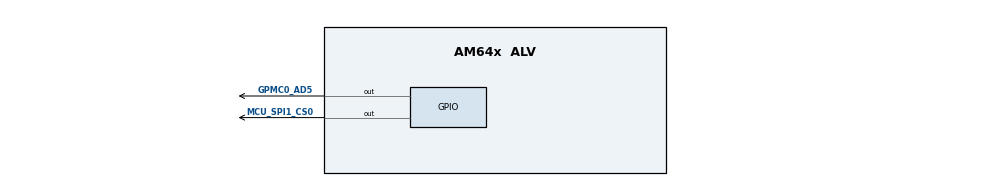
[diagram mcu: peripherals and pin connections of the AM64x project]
/**
 * @cliArgs --device "AM64x" --package "ALV" --part "Default" --context "r5fss0-0" --product "INDUSTRIAL_COMMUNICATIONS_SDK@09.01.00"
 * @versions {"tool":"1.19.0+3426"}
 */

/**
 * Import the modules used in this configuration.
 */
const eeprom     = scripting.addModule("/board/eeprom/eeprom", {}, false);
const eeprom1    = eeprom.addInstance();
const led        = scripting.addModule("/board/led/led", {}, false);
const led1       = led.addInstance();
const led2       = led.addInstance();
const led3       = led.addInstance();
const gpio       = scripting.addModule("/drivers/gpio/gpio", {}, false);
const gpio1      = gpio.addInstance();
const gpio2      = gpio.addInstance();
const gpio3      = gpio.addInstance();
const i2c        = scripting.addModule("/drivers/i2c/i2c", {}, false);
const i2c1       = i2c.addInstance();
const i2c2       = i2c.addInstance();
const ipc        = scripting.addModule("/drivers/ipc/ipc");
const pruicss    = scripting.addModule("/drivers/pruicss/pruicss", {}, false);
const pruicss1   = pruicss.addInstance();
const udma       = scripting.addModule("/drivers/udma/udma", {}, false);
const udma1      = udma.addInstance();
const profinet   = scripting.addModule("/industrial_comms/profinet/profinet", {}, false);
const profinet1  = profinet.addInstance();
const debug_log  = scripting.addModule("/kernel/dpl/debug_log");
const mpu_armv7  = scripting.addModule("/kernel/dpl/mpu_armv7", {}, false);
const mpu_armv71 = mpu_armv7.addInstance();
const mpu_armv72 = mpu_armv7.addInstance();
const mpu_armv73 = mpu_armv7.addInstance();
const mpu_armv74 = mpu_armv7.addInstance();
const mpu_armv75 = mpu_armv7.addInstance();
const mpu_armv76 = mpu_armv7.addInstance();
const mpu_armv77 = mpu_armv7.addInstance();
const mpu_armv78 = mpu_armv7.addInstance();
const mpu_armv79 = mpu_armv7.addInstance();

/**
 * Write custom configuration values to the imported modules.
 */
eeprom1.$name = "CONFIG_EEPROM0";

led1.$name = "CONFIG_LED0";

led2.$name = "CONFIG_LED1";

led3.$name = "CONFIG_LED2";
led3.name  = "TPIC2810";

gpio1.pinDir                   = "OUTPUT";
gpio1.useMcuDomainPeripherals  = true;
gpio1.$name                    = "CONFIG_GPIO2";
gpio1.MCU_GPIO.$assign         = "MCU_GPIO0";
gpio1.MCU_GPIO.gpioPin.$assign = "MCU_SPI1_CS0";

gpio2.pinDir               = "OUTPUT";
gpio2.$name                = "CONFIG_GPIO0";
led1.peripheralDriver      = gpio2;
gpio2.GPIO.$assign         = "GPIO0";
gpio2.GPIO.gpioPin.$assign = "GPMC0_AD5";

gpio3.$name           = "CONFIG_GPIO1";
led2.peripheralDriver = gpio3;
gpio3.GPIO.$assign    = "GPIO1";

i2c1.$name               = "CONFIG_I2C0";
eeprom1.peripheralDriver = i2c1;
led3.peripheralDriver    = i2c1;
i2c1.I2C.$assign         = "I2C0";
i2c1.I2C.SCL.$assign     = "I2C0_SCL";
i2c1.I2C.SDA.$assign     = "I2C0_SDA";

i2c2.$name           = "CONFIG_I2C1";
i2c2.I2C.$assign     = "I2C1";
i2c2.I2C.SCL.$assign = "I2C1_SCL";
i2c2.I2C.SDA.$assign = "I2C1_SDA";

ipc.r5fss1_0 = "NONE";
ipc.r5fss1_1 = "NONE";
ipc.m4fss0_0 = "NONE";

udma1.$name    = "CONFIG_UDMA_PKTDMA0";
udma1.instance = "PKTDMA_0";

profinet1.$name                         = "CONFIG_PROFINET0";
profinet1.icss_emac[0].$name            = "CONFIG_ICSS_EMAC0";
profinet1.icss_emac[0].learningEnable   = true;
profinet1.icss_emac[0].txTaskPriority   = 10;
profinet1.icss_emac[0].rxTaskPriority   = 6;
profinet1.icss_emac[0].linkTaskPriority = 12;
profinet1.ethphy1[0].$name              = "CONFIG_ETHPHY0";
profinet1.ethphy2[0].$name              = "CONFIG_ETHPHY1";

pruicss1.instance                        = "ICSSG1";
pruicss1.$name                           = "CONFIG_PRU_ICSS1";
profinet1.icss                           = pruicss1;
pruicss1.AdditionalICSSSettings[0].$name = "CONFIG_PRU_ICSS_IO0";
pruicss1.intcMapping.create(1);
pruicss1.intcMapping[0].$name            = "CONFIG_ICSS1_INTC_MAPPING0";
pruicss1.intcMapping[0].event            = "41";
pruicss1.intcMapping[0].channel          = "7";
pruicss1.intcMapping[0].host             = "8";

debug_log.enableUartLog        = true;
debug_log.enableCssLog         = false;
debug_log.uartLog.$name        = "CONFIG_UART0";
debug_log.uartLog.UART.$assign = "USART0";

const uart_v0_template  = scripting.addModule("/drivers/uart/v0/uart_v0_template", {}, false);
const uart_v0_template1 = uart_v0_template.addInstance({}, false);
uart_v0_template1.$name = "drivers_uart_v0_uart_v0_template0";
debug_log.uartLog.child = uart_v0_template1;

mpu_armv71.$name             = "CONFIG_MPU_REGION0";
mpu_armv71.size              = 31;
mpu_armv71.attributes        = "Device";
mpu_armv71.accessPermissions = "Supervisor RD+WR, User RD";
mpu_armv71.allowExecute      = false;

mpu_armv72.$name             = "CONFIG_MPU_REGION1";
mpu_armv72.size              = 15;
mpu_armv72.accessPermissions = "Supervisor RD+WR, User RD";

mpu_armv73.$name             = "CONFIG_MPU_REGION2";
mpu_armv73.baseAddr          = 0x41010000;
mpu_armv73.size              = 15;
mpu_armv73.accessPermissions = "Supervisor RD+WR, User RD";

mpu_armv74.$name             = "CONFIG_MPU_REGION3";
mpu_armv74.accessPermissions = "Supervisor RD+WR, User RD";
mpu_armv74.baseAddr          = 0x70000000;
mpu_armv74.size              = 21;

mpu_armv75.$name             = "CONFIG_MPU_REGION4";
mpu_armv75.accessPermissions = "Supervisor RD+WR, User RD";
mpu_armv75.baseAddr          = 0x80000000;
mpu_armv75.size              = 31;

mpu_armv76.$name             = "CONFIG_MPU_REGION5";
mpu_armv76.accessPermissions = "Supervisor RD+WR, User RD";
mpu_armv76.baseAddr          = 0xA5000000;
mpu_armv76.size              = 23;
mpu_armv76.attributes        = "NonCached";

mpu_armv77.$name    = "CONFIG_MPU_REGION6";
mpu_armv77.size     = 27;
mpu_armv77.baseAddr = 0x60000000;

mpu_armv78.$name      = "CONFIG_MPU_REGION7";
mpu_armv78.attributes = "NonCached";
mpu_armv78.baseAddr   = 0x82000000;
mpu_armv78.size       = 25;

mpu_armv79.$name      = "CONFIG_MPU_REGION8";
mpu_armv79.baseAddr   = 0x701F0000;
mpu_armv79.size       = 16;
mpu_armv79.attributes = "NonCached";

/**
 * Pinmux solution for unlocked pins/peripherals. This ensures that minor changes to the automatic solver in a future
 * version of the tool will not impact the pinmux you originally saw.  These lines can be completely deleted in order to
 * re-solve from scratch.
 */
gpio3.GPIO.gpioPin.$suggestSolution                        = "PRG0_PRU0_GPO0";
profinet1.PRU_ICSSG1_MDIO.$suggestSolution                 = "PRU_ICSSG1_MDIO0";
profinet1.PRU_ICSSG1_MDIO.MDC.$suggestSolution             = "PRG1_MDIO0_MDC";
profinet1.PRU_ICSSG1_MDIO.MDIO.$suggestSolution            = "PRG1_MDIO0_MDIO";
profinet1.PRU_ICSSG1_MII_G_RT.$suggestSolution             = "PRU_ICSSG1_MII_G_RT";
profinet1.PRU_ICSSG1_MII_G_RT.MII0_RXD0.$suggestSolution   = "PRG1_PRU0_GPO0";
profinet1.PRU_ICSSG1_MII_G_RT.MII0_RXD1.$suggestSolution   = "PRG1_PRU0_GPO1";
profinet1.PRU_ICSSG1_MII_G_RT.MII0_RXD2.$suggestSolution   = "PRG1_PRU0_GPO2";
profinet1.PRU_ICSSG1_MII_G_RT.MII0_RXD3.$suggestSolution   = "PRG1_PRU0_GPO3";
profinet1.PRU_ICSSG1_MII_G_RT.MII0_RXDV.$suggestSolution   = "PRG1_PRU0_GPO4";
profinet1.PRU_ICSSG1_MII_G_RT.MII0_RXER.$suggestSolution   = "PRG1_PRU0_GPO5";
profinet1.PRU_ICSSG1_MII_G_RT.MII0_TXD0.$suggestSolution   = "PRG1_PRU0_GPO11";
profinet1.PRU_ICSSG1_MII_G_RT.MII0_TXD1.$suggestSolution   = "PRG1_PRU0_GPO12";
profinet1.PRU_ICSSG1_MII_G_RT.MII0_TXD2.$suggestSolution   = "PRG1_PRU0_GPO13";
profinet1.PRU_ICSSG1_MII_G_RT.MII0_TXD3.$suggestSolution   = "PRG1_PRU0_GPO14";
profinet1.PRU_ICSSG1_MII_G_RT.MII0_TXEN.$suggestSolution   = "PRG1_PRU0_GPO15";
profinet1.PRU_ICSSG1_MII_G_RT.MII1_RXD0.$suggestSolution   = "PRG1_PRU1_GPO0";
profinet1.PRU_ICSSG1_MII_G_RT.MII1_RXD1.$suggestSolution   = "PRG1_PRU1_GPO1";
profinet1.PRU_ICSSG1_MII_G_RT.MII1_RXD2.$suggestSolution   = "PRG1_PRU1_GPO2";
profinet1.PRU_ICSSG1_MII_G_RT.MII1_RXD3.$suggestSolution   = "PRG1_PRU1_GPO3";
profinet1.PRU_ICSSG1_MII_G_RT.MII1_RXDV.$suggestSolution   = "PRG1_PRU1_GPO4";
profinet1.PRU_ICSSG1_MII_G_RT.MII1_RXER.$suggestSolution   = "PRG1_PRU1_GPO5";
profinet1.PRU_ICSSG1_MII_G_RT.MII1_TXD0.$suggestSolution   = "PRG1_PRU1_GPO11";
profinet1.PRU_ICSSG1_MII_G_RT.MII1_TXD1.$suggestSolution   = "PRG1_PRU1_GPO12";
profinet1.PRU_ICSSG1_MII_G_RT.MII1_TXD2.$suggestSolution   = "PRG1_PRU1_GPO13";
profinet1.PRU_ICSSG1_MII_G_RT.MII1_TXD3.$suggestSolution   = "PRG1_PRU1_GPO14";
profinet1.PRU_ICSSG1_MII_G_RT.MII1_TXEN.$suggestSolution   = "PRG1_PRU1_GPO15";
profinet1.PRU_ICSSG1_MII_G_RT.MII_MR0_CLK.$suggestSolution = "PRG1_PRU0_GPO6";
profinet1.PRU_ICSSG1_MII_G_RT.MII_MR1_CLK.$suggestSolution = "PRG1_PRU1_GPO6";
profinet1.PRU_ICSSG1_MII_G_RT.MII_MT0_CLK.$suggestSolution = "PRG1_PRU0_GPO16";
profinet1.PRU_ICSSG1_MII_G_RT.MII_MT1_CLK.$suggestSolution = "PRG1_PRU1_GPO16";
debug_log.uartLog.UART.RXD.$suggestSolution                = "UART0_RXD";
debug_log.uartLog.UART.TXD.$suggestSolution                = "UART0_TXD";
